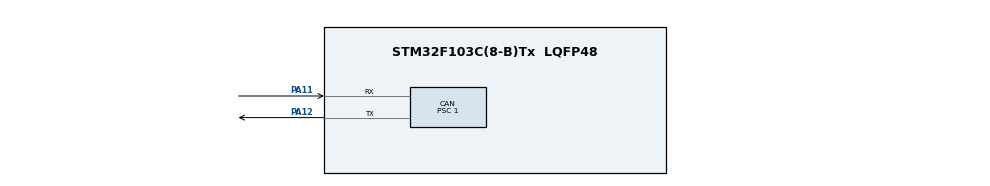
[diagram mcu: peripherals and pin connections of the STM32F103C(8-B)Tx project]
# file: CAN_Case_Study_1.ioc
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CAN.BS1=CAN_BS1_6TQ
CAN.CalculateTimeBit=1000
CAN.CalculateTimeQuantum=125.0
CAN.Mode=CAN_MODE_LOOPBACK
CAN.Prescaler=1
Mcu.Family=STM32F1
Mcu.Name=STM32F103C(8-B)Tx
Mcu.Package=LQFP48
NVIC.PriorityGroup=NVIC_PRIORITYGROUP_4
PA11.Mode=Master
PA11.Signal=CAN_RX
PA12.Mode=Master
PA12.Signal=CAN_TX
ProjectManager.HeapSize=0x200
ProjectManager.StackSize=0x400
ProjectManager.TargetToolchain=STM32CubeIDE
RCC.APB1Freq_Value=8000000
RCC.APB2Freq_Value=8000000
VP_SYS_VS_ND.Mode=No_Debug
board=custom

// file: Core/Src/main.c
/* USER CODE BEGIN Header */
/**
  ******************************************************************************
  * @file           : main.c
  * @brief          : Main program body
  ******************************************************************************
  * @attention
  *
  * <h2><center>&copy; Copyright (c) 2024 STMicroelectronics.
  * All rights reserved.</center></h2>
  *
  * This software component is licensed by ST under BSD 3-Clause license,
  * the "License"; You may not use this file except in compliance with the
  * License. You may obtain a copy of the License at:
  *                        opensource.org/licenses/BSD-3-Clause
  *
  ******************************************************************************
  */
/* USER CODE END Header */
#include "main.h"

CAN_HandleTypeDef hcan;

void SystemClock_Config(void);
static void MX_GPIO_Init(void);
static void MX_CAN_Init(void);
/* USER CODE BEGIN PFP */
static void CAN_Filter_init(uint16_t filterID, uint16_t filterMask);
static uint32_t CAN_TX(uint32_t stdID, uint8_t *pPayload);
static void CAN_RX(uint16_t stdID, uint8_t* buffer);

/* USER CODE END PFP */

int main(void)
{
  /* USER CODE BEGIN 1 */
	uint8_t data[8] = "Frame :";
	uint8_t buffer[8];
	uint8_t frameNo = 0;

  /* USER CODE END 1 */

  /* MCU Configuration--------------------------------------------------------*/

  /* Reset of all peripherals, Initializes the Flash interface and the Systick. */
  HAL_Init();

  /* Configure the system clock */
  SystemClock_Config();

  /* Initialize all configured peripherals */
  MX_GPIO_Init();
  MX_CAN_Init();
  /* USER CODE BEGIN 2 */

  /*(#) Configure the reception filters using the following configuration functions:
		(++) HAL_CAN_ConfigFilter()*/
  CAN_Filter_init(0x3FF, 0x7FF);

  /*(#) Start the CAN module using HAL_CAN_Start() function. At this level
            the node is active on the bus: it receive messages, and can send
            messages.*/
  HAL_CAN_Start(&hcan);

  /* USER CODE END 2 */

  /* Infinite loop */
  /* USER CODE BEGIN WHILE */
  while (1)
  {
	  data[7] = frameNo++;

    /* USER CODE END WHILE */
	  CAN_TX(0x3FF, data);

	  CAN_RX(0x3FF, buffer);
  }
}

void SystemClock_Config(void)
{
  RCC_OscInitTypeDef RCC_OscInitStruct = {0};
  RCC_ClkInitTypeDef RCC_ClkInitStruct = {0};

  /** Initializes the RCC Oscillators according to the specified parameters
  * in the RCC_OscInitTypeDef structure.
  */
  RCC_OscInitStruct.OscillatorType = RCC_OSCILLATORTYPE_HSI;
  RCC_OscInitStruct.HSIState = RCC_HSI_ON;
  RCC_OscInitStruct.HSICalibrationValue = RCC_HSICALIBRATION_DEFAULT;
  RCC_OscInitStruct.PLL.PLLState = RCC_PLL_NONE;
  if (HAL_RCC_OscConfig(&RCC_OscInitStruct) != HAL_OK)
  {
    Error_Handler();
  }
  /** Initializes the CPU, AHB and APB buses clocks
  */
  RCC_ClkInitStruct.ClockType = RCC_CLOCKTYPE_HCLK|RCC_CLOCKTYPE_SYSCLK
                              |RCC_CLOCKTYPE_PCLK1|RCC_CLOCKTYPE_PCLK2;
  RCC_ClkInitStruct.SYSCLKSource = RCC_SYSCLKSOURCE_HSI;
  RCC_ClkInitStruct.AHBCLKDivider = RCC_SYSCLK_DIV1;
  RCC_ClkInitStruct.APB1CLKDivider = RCC_HCLK_DIV1;
  RCC_ClkInitStruct.APB2CLKDivider = RCC_HCLK_DIV1;

  if (HAL_RCC_ClockConfig(&RCC_ClkInitStruct, FLASH_LATENCY_0) != HAL_OK)
  {
    Error_Handler();
  }
}

static void MX_CAN_Init(void)
{

  hcan.Instance = CAN1;
  hcan.Init.Prescaler = 1;
  hcan.Init.Mode = CAN_MODE_LOOPBACK;
  hcan.Init.SyncJumpWidth = CAN_SJW_1TQ;
  hcan.Init.TimeSeg1 = CAN_BS1_6TQ;
  hcan.Init.TimeSeg2 = CAN_BS2_1TQ;
  hcan.Init.TimeTriggeredMode = DISABLE;
  hcan.Init.AutoBusOff = DISABLE;
  hcan.Init.AutoWakeUp = DISABLE;
  hcan.Init.AutoRetransmission = DISABLE;
  hcan.Init.ReceiveFifoLocked = DISABLE;
  hcan.Init.TransmitFifoPriority = DISABLE;
  if (HAL_CAN_Init(&hcan) != HAL_OK)
  {
    Error_Handler();
  }

}

static void CAN_Filter_init(uint16_t filterID, uint16_t filterMask)
{

	CAN_FilterTypeDef sFilterConfig;

	sFilterConfig.FilterActivation = ENABLE;
	sFilterConfig.FilterBank = 0;
	sFilterConfig.FilterFIFOAssignment = 0;
	sFilterConfig.FilterMode = CAN_FILTERMODE_IDMASK;
	sFilterConfig.FilterScale = CAN_FILTERSCALE_32BIT;
	sFilterConfig.FilterIdHigh = filterID << 5;  /*Specify the STDID*/
	sFilterConfig.FilterIdLow = 0x0000;
	sFilterConfig.FilterMaskIdHigh = filterMask << 5;
	sFilterConfig.FilterMaskIdLow = 0x0000;

	HAL_CAN_ConfigFilter(&hcan, &sFilterConfig);
}

static uint32_t CAN_TX(uint32_t stdID, uint8_t *pPayload)
{
	uint32_t txMailboxNum;
	CAN_TxHeaderTypeDef pHeader;
	pHeader.DLC = 8;
	pHeader.StdId = stdID;
	pHeader.IDE = CAN_ID_STD;
	pHeader.RTR = CAN_RTR_DATA;

	/**** Polling mode operation ***
      ==============================
    [..]
      (#) Transmission:
            (++) Monitor the Tx mailboxes availability until at least one Tx
                 mailbox is free, using HAL_CAN_GetTxMailboxesFreeLevel().
            (++) Then request transmission of a message using
                 HAL_CAN_AddTxMessage().*/
	while(HAL_CAN_GetTxMailboxesFreeLevel(&hcan) == 0);

	if(HAL_CAN_AddTxMessage(&hcan, &pHeader, pPayload, &txMailboxNum) != HAL_OK)
	{
		Error_Handler();

	}
	/*
	  (++) HAL_CAN_IsTxMessagePending() to check if a message is pending
                 in a Tx mailbox.
	 */

	while(HAL_CAN_IsTxMessagePending(&hcan, txMailboxNum) == 1); //Wait untill the message is sent

	return txMailboxNum;
}

static void CAN_RX(uint16_t stdID, uint8_t* buffer)
{
	CAN_RxHeaderTypeDef pHeader;
	pHeader.DLC = 8;
	pHeader.IDE = CAN_ID_STD;
	pHeader.RTR = CAN_RTR_DATA;
	pHeader.StdId = stdID;

	/**** Polling mode operation ***
      ==============================
    [..]
      (#) Reception:
            (++) Monitor reception of message using HAL_CAN_GetRxFifoFillLevel()
                 until at least one message is received.
            (++) Then get the message using HAL_CAN_GetRxMessage().
	 * */

	while(HAL_CAN_GetRxFifoFillLevel(&hcan, CAN_RX_FIFO0) == 0);

	if(HAL_CAN_GetRxMessage(&hcan, CAN_RX_FIFO0, &pHeader, buffer) != HAL_OK)
	{
		Error_Handler();
	}

}

static void MX_GPIO_Init(void)
{

  /* GPIO Ports Clock Enable */
  __HAL_RCC_GPIOA_CLK_ENABLE();

}

void Error_Handler(void)
{
  /* USER CODE BEGIN Error_Handler_Debug */
  /* User can add his own implementation to report the HAL error return state */
	while(1);
  /* USER CODE END Error_Handler_Debug */
}

/************************ (C) COPYRIGHT STMicroelectronics *****END OF FILE****/
